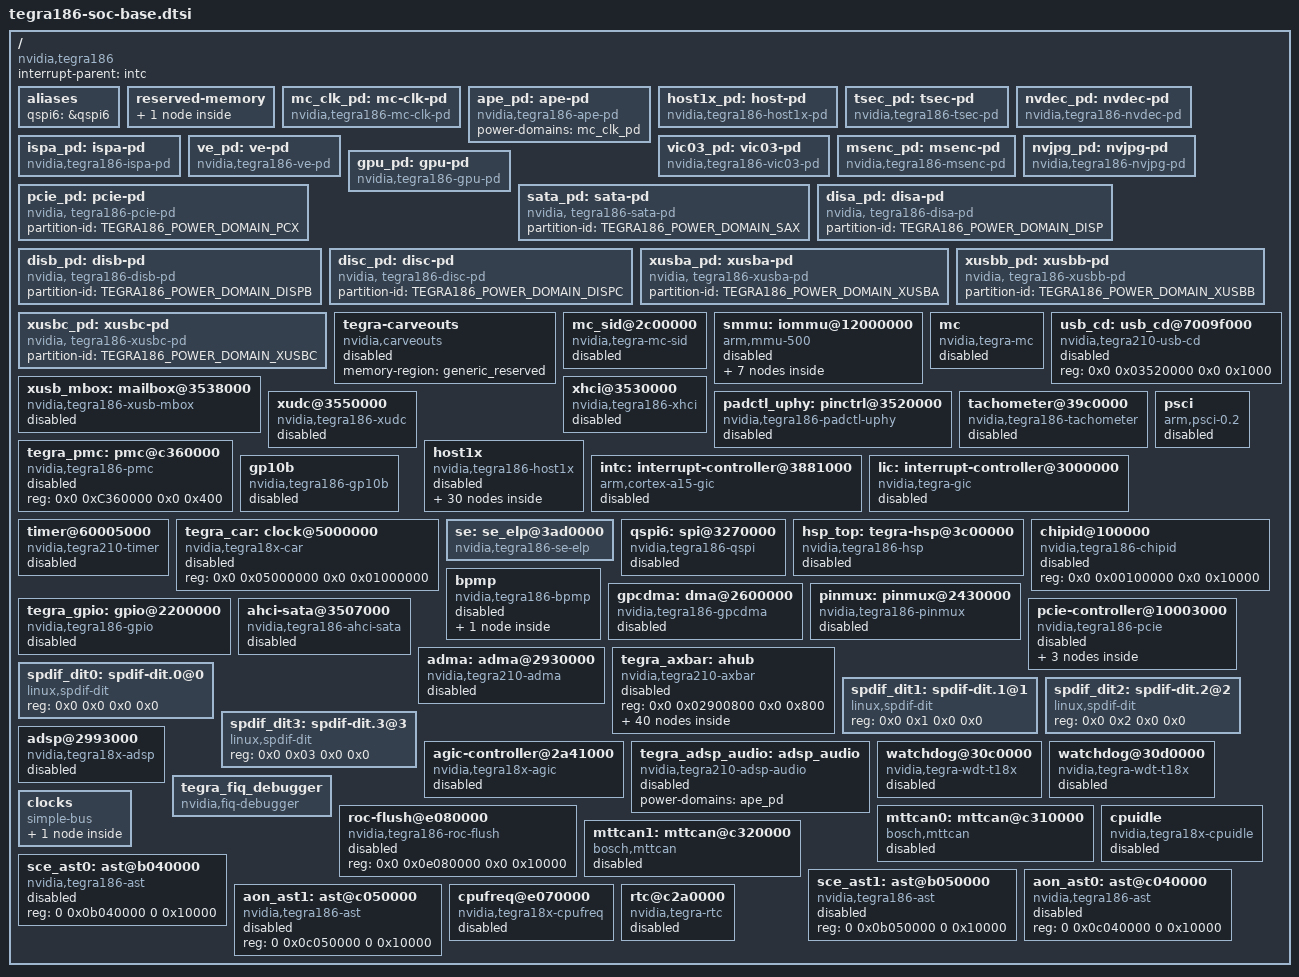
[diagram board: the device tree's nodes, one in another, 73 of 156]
/*
 * tegra186-soc-base.dtsi: SoC Base DTSI file.
 *
 * Copyright (c) 2014-2015, NVIDIA CORPORATION.  All rights reserved.
 *
 * This program is free software; you can redistribute it and/or modify
 * it under the terms of the GNU General Public License as published by
 * the Free Software Foundation; version 2 of the License.
 *
 * This program is distributed in the hope that it will be useful, but WITHOUT
 * ANY WARRANTY; without even the implied warranty of MERCHANTABILITY or
 * FITNESS FOR A PARTICULAR PURPOSE.  See the GNU General Public License for
 * more details.
 *
 * You should have received a copy of the GNU General Public License along
 * with this program; if not, write to the Free Software Foundation, Inc.,
 * 51 Franklin Street, Fifth Floor, Boston, MA  02110-1301, USA.
 *
 */

#include <dt-bindings/memory/tegra-swgroup.h>
#include <dt-bindings/memory/tegra186-swgroup.h>
#include <dt-bindings/display/tegra-dc.h>
#include "../../../../include/dt-bindings/clock/tegra186-clock.h"
#include "../../../../include/dt-bindings/reset/tegra186-reset.h"
#include "../../../../include/dt-bindings/interrupt/tegra186-irq.h"
#include "tegra186-soc/tegra186-sdhci.dtsi"
#include "tegra186-soc/tegra186-soc-ufshc.dtsi"
#include "tegra186-soc/tegra186-soc-i2c.dtsi"
#include "tegra186-soc/tegra186-soc-spi.dtsi"
#include "tegra186-soc/tegra186-soc-pwm.dtsi"
#include "../../../../include/dt-bindings/soc/tegra186-powergate.h"
#include "../../../../include/dt-bindings/pinctrl/pinctrl-tegra-padctl-uphy.h"
#include "tegra186-soc/tegra186-soc-uart.dtsi"
#include "tegra186-soc/tegra186-soc-eqos.dtsi"

/ {
	compatible = "nvidia,tegra186";
	interrupt-parent = <&intc>;
	#address-cells = <2>;
	#size-cells = <2>;

	aliases {
		qspi6 = &qspi6;
	};

	reserved-memory {
		#address-cells = <2>;
		#size-cells = <2>;
		ranges;

		generic_reserved: generic_carveout {
			compatible = "nvidia,generic_carveout";
			size = <0 0x20000000>;
			alignment = <0 0x100000>;
			no-map;
			status = "disabled";
		};
	};

	mc_clk_pd: mc-clk-pd {
		compatible = "nvidia,tegra186-mc-clk-pd";
		#power-domain-cells = <0>;
	};

	ape_pd: ape-pd {
		compatible = "nvidia,tegra186-ape-pd";
		#power-domain-cells = <0>;
		power-domains = <&mc_clk_pd>;
	};

	host1x_pd: host-pd {
		compatible = "nvidia,tegra186-host1x-pd";
		is_off;
		host1x;
		#power-domain-cells = <0>;
		power-domains = <&mc_clk_pd>;
	};

	tsec_pd: tsec-pd {
		compatible = "nvidia,tegra186-tsec-pd";
		is_off;
		#power-domain-cells = <0>;
		power-domains = <&host1x_pd>;
	};

	nvdec_pd: nvdec-pd {
		compatible = "nvidia,tegra186-nvdec-pd";
		is_off;
		#power-domain-cells = <0>;
		power-domains = <&host1x_pd>;
		partition-id = <TEGRA186_POWER_DOMAIN_NVDEC>;
	};

	ispa_pd: ispa-pd {
		compatible = "nvidia,tegra186-ispa-pd";
		is_off;
		#power-domain-cells = <0>;
		power-domains = <&host1x_pd>;
		partition-id = <TEGRA186_POWER_DOMAIN_ISPA>;
	};

	ve_pd: ve-pd {
		compatible = "nvidia,tegra186-ve-pd";
		is_off;
		#power-domain-cells = <0>;
		power-domains = <&host1x_pd>;
		partition-id = <TEGRA186_POWER_DOMAIN_VE>;
	};

	vic03_pd: vic03-pd {
		compatible = "nvidia,tegra186-vic03-pd";
		is_off;
		#power-domain-cells = <0>;
		power-domains = <&host1x_pd>;
		partition-id = <TEGRA186_POWER_DOMAIN_VIC>;
	};

	msenc_pd: msenc-pd {
		compatible = "nvidia,tegra186-msenc-pd";
		is_off;
		#power-domain-cells = <0>;
		power-domains = <&host1x_pd>;
		partition-id = <TEGRA186_POWER_DOMAIN_MPE>;
	};

	nvjpg_pd: nvjpg-pd {
		compatible = "nvidia,tegra186-nvjpg-pd";
		is_off;
		#power-domain-cells = <0>;
		power-domains = <&host1x_pd>;
		partition-id = <TEGRA186_POWER_DOMAIN_NVJPG>;
	};

	gpu_pd: gpu-pd {
		compatible = "nvidia,tegra186-gpu-pd";
		is_off;
		#power-domain-cells = <0>;
		power-domains = <&host1x_pd>;
		partition-id = <TEGRA186_POWER_DOMAIN_GPU>;
	};

	pcie_pd: pcie-pd {
		compatible = "nvidia, tegra186-pcie-pd";
		#power-domain-cells = <0>;
		partition-id = <TEGRA186_POWER_DOMAIN_PCX>;
	};

	sata_pd: sata-pd {
		compatible = "nvidia, tegra186-sata-pd";
		#power-domain-cells = <0>;
		partition-id = <TEGRA186_POWER_DOMAIN_SAX>;
	};

	disa_pd: disa-pd {
		compatible = "nvidia, tegra186-disa-pd";
		#power-domain-cells = <0>;
		partition-id = <TEGRA186_POWER_DOMAIN_DISP>;
	};

	disb_pd: disb-pd {
		compatible = "nvidia, tegra186-disb-pd";
		#power-domain-cells = <0>;
		partition-id = <TEGRA186_POWER_DOMAIN_DISPB>;
	};

	disc_pd: disc-pd {
		compatible = "nvidia, tegra186-disc-pd";
		#power-domain-cells = <0>;
		partition-id = <TEGRA186_POWER_DOMAIN_DISPC>;
	};

	xusba_pd: xusba-pd {
		compatible = "nvidia, tegra186-xusba-pd";
		#power-domain-cells = <0>;
		partition-id = <TEGRA186_POWER_DOMAIN_XUSBA>;
	};

	xusbb_pd: xusbb-pd {
		compatible = "nvidia, tegra186-xusbb-pd";
		#power-domain-cells = <0>;
		partition-id = <TEGRA186_POWER_DOMAIN_XUSBB>;
	};

	xusbc_pd: xusbc-pd {
		compatible = "nvidia, tegra186-xusbc-pd";
		#power-domain-cells = <0>;
		partition-id = <TEGRA186_POWER_DOMAIN_XUSBC>;
	};

	tegra-carveouts {
		compatible = "nvidia,carveouts";
		memory-region = <&generic_reserved>;
		status = "disabled";
	};

	mc_sid@2c00000 {
		compatible = "nvidia,tegra-mc-sid";
 		reg = <0x0 0x02c00000 0x0 0x00010000>, /* MC_SID_BASE */
 		      <0x0 0x02c10000 0x0 0x00010000>; /* MC_BASE */
		status = "disabled";
	};

	/* HACK: Populate earlier than other device */
	smmu: iommu@12000000{
		compatible = "arm,mmu-500";
		reg = <0x0 0x12000000 0x0 0x01000000>; /* 16MB */
		#global-interrupts = <2>;
		interrupts = <0 170 4>,
			     <0 171 4>;

		mmu-masters = <&{/gp10b}		TEGRA_SWGROUP_GPUB>,
			      <&host1x			TEGRA_SWGROUP_HC>,
			      <&{/host1x/nvcsi@150c0000}	TEGRA_SWGROUP_NVCSI>,
			      <&{/host1x/vic@15340000}		TEGRA_SWGROUP_VIC>,
			      <&{/host1x/vi@15700000}		TEGRA_SWGROUP_VI>,
			      <&{/host1x/isp@15600000}		TEGRA_SWGROUP_ISP>,
			      <&{/host1x/nvdec@15480000}	TEGRA_SWGROUP_NVDEC>,
			      <&{/host1x/nvenc@154c0000}	TEGRA_SWGROUP_NVENC>,
			      <&{/host1x/nvjpg@15380000}		TEGRA_SWGROUP_NVJPG>,
			      <&{/host1x/nvdisplay@15200000}	TEGRA_SWGROUP_NVDISPLAY>,
			      <&{/host1x/nvdisplay@15210000}	TEGRA_SWGROUP_NVDISPLAY>,
			      <&{/host1x/nvdisplay@15220000}	TEGRA_SWGROUP_NVDISPLAY>,
			      <&{/host1x/tsec@15500000}		TEGRA_SWGROUP_TSEC>,
			      <&{/host1x/tsecb@15100000}	TEGRA_SWGROUP_TSECB>,
			      <&{/host1x/se@15810000}		TEGRA_SWGROUP_SE>,
			      <&{/host1x/se@15820000}		TEGRA_SWGROUP_SE1>,
			      <&{/host1x/se@15830000}		TEGRA_SWGROUP_SE2>,
			      <&{/host1x/se@15840000}		TEGRA_SWGROUP_SE3>,
			      <&{/sdhci@3460000}	TEGRA_SWGROUP_SDMMC4A>,
			      <&{/sdhci@3440000}	TEGRA_SWGROUP_SDMMC3A>,
			      <&{/sdhci@3420000}	TEGRA_SWGROUP_SDMMC2A>,
			      <&{/sdhci@3400000}	TEGRA_SWGROUP_SDMMC1A>,
			      <&{/xhci@3530000}		TEGRA_SWGROUP_XUSB_HOST>,
			      <&{/xudc@3550000}		TEGRA_SWGROUP_XUSB_DEV>,
			      <&{/ahci-sata@3507000}	TEGRA_SWGROUP_SATA2>,
			      <&{/bpmp}			TEGRA_SWGROUP_BPMP>,
			      <&{/dma@2600000}		TEGRA_SWGROUP_AXIS>,
			      <&host1x_ctx0		TEGRA_SWGROUP_HOST1X_CTX0>,
			      <&host1x_ctx1		TEGRA_SWGROUP_HOST1X_CTX1>,
			      <&host1x_ctx2		TEGRA_SWGROUP_HOST1X_CTX2>,
			      <&host1x_ctx3		TEGRA_SWGROUP_HOST1X_CTX3>,
			      <&host1x_ctx4		TEGRA_SWGROUP_HOST1X_CTX4>,
			      <&host1x_ctx5		TEGRA_SWGROUP_HOST1X_CTX5>,
			      <&host1x_ctx6		TEGRA_SWGROUP_HOST1X_CTX6>,
			      <&host1x_ctx7		TEGRA_SWGROUP_HOST1X_CTX7>;

		domains = <&ppcs_as TEGRA_SWGROUP_CELLS3(PPCS, PPCS1, PPCS2)>,
			  <&gpu_as TEGRA_SWGROUP_CELLS(GPUB)>,
			  <&ape_as TEGRA_SWGROUP_CELLS(APE)>,
			  <&dc_as TEGRA_SWGROUP_CELLS3(DC, DC12, DCB)>,
			  <&host1x_as 0x008c0940 0x6002225a>, /* HC,ISP,NVENC,VI,VIC,TSEC,NVDEC,SE,NVJPG,SE1,TSECB,NVCSI,NVDISPLAY,SE2,SE3 */
			  <&host1x_as TEGRA_SWGROUP_CELLS(HOST1X_CTX0)>,
			  <&host1x_as TEGRA_SWGROUP_CELLS(HOST1X_CTX1)>,
			  <&host1x_as TEGRA_SWGROUP_CELLS(HOST1X_CTX2)>,
			  <&host1x_as TEGRA_SWGROUP_CELLS(HOST1X_CTX3)>,
			  <&host1x_as TEGRA_SWGROUP_CELLS(HOST1X_CTX4)>,
			  <&host1x_as TEGRA_SWGROUP_CELLS(HOST1X_CTX5)>,
			  <&host1x_as TEGRA_SWGROUP_CELLS(HOST1X_CTX6)>,
			  <&host1x_as TEGRA_SWGROUP_CELLS(HOST1X_CTX7)>,
			  <&common_as TEGRA_SWGROUP_CELLS(SDMMC1A)>,
			  <&common_as TEGRA_SWGROUP_CELLS(SDMMC2A)>,
			  <&common_as TEGRA_SWGROUP_CELLS(SDMMC3A)>,
			  <&common_as TEGRA_SWGROUP_CELLS(SDMMC4A)>,
			  <&common_as TEGRA_SWGROUP_CELLS(XUSB_HOST)>,
			  <&common_as TEGRA_SWGROUP_CELLS(XUSB_DEV)>,
			  <&common_as TEGRA_SWGROUP_CELLS(AXIS)>,
			  <&common_as TEGRA_SWGROUP_CELLS(BPMP)>,
			  <&common_as TEGRA_SWGROUP_CELLS(AFI)>;

		status = "disabled";

		address-space-prop {
			host1x_as: host1x {
				iova-start = <0x0 0x5a500000>;
				iova-size = <0x0 0x7FF00000>;
				alignment = <0xFFFFF>;
				num-pf-page = <0>;
				gap-page = <1>;
			};
			common_as: common {
				iova-start = <0x0 0x80000000>;
				iova-size = <0x0 0x7FF00000>;
				alignment = <0xFFFFF>;
				num-pf-page = <0>;
				gap-page = <1>;
			};
			ppcs_as: ppcs {
				iova-start = <0x0 0x80000000>;
				iova-size = <0x0 0x7FF00000>;
				alignment = <0xFFFFF>;
				num-pf-page = <1>;
				gap-page = <1>;
			};
			dc_as: dc {
				iova-start = <0x0 0x00010000>;
				iova-size = <0x0 0xFFFEFFFF>;
				alignment = <0xFFFFF>;
				num-pf-page = <0>;
				gap-page = <0>;
			};
			gpu_as: gpu {
				iova-start = <0x0 0x00100000>;
				iova-size = <0x0 0xFFEFFFFF>;
				alignment = <0xFFFFF>;
				num-pf-page = <0>;
				gap-page = <0>;
			};
			ape_as: ape {
				iova-start = <0x0 0x40000000>;
				iova-size = <0x0 0xC0000000>;
				alignment = <0xFFFFF>;
				num-pf-page = <0>;
				gap-page = <1>;
			};
		};
	};

	mc {
		compatible = "nvidia,tegra-mc";

		reg-ranges = <1>;
		reg        = <0x0 0x2c10000 0x0 0x1000   /* Broadcast channel */
			      0x0 0x2c20000 0x0 0x1000   /* MC0 */
			      0x0 0x2c30000 0x0 0x1000   /* MC1 */
			      0x0 0x2c40000 0x0 0x1000   /* MC2 */
			      0x0 0x2c50000 0x0 0x1000>; /* MC3 */

		interrupts = <0 223 0x4>;
		int_count  = <8>;
		int_mask   = <0xf3140>;

		channels   = <4>;
		status = "disabled";
        };

	usb_cd: usb_cd@7009f000 {
		compatible = "nvidia,tegra210-usb-cd";
		reg = <0x0 0x03520000 0x0 0x1000>;
		#extcon-cells = <1>;
		status = "disabled";
	};

	xusb_mbox: mailbox@3538000 {
		compatible = "nvidia,tegra186-xusb-mbox";
		reg = <0x0 0x03538000 0x0 0x1000>;
		interrupts = <0 164 0x4>;

		#mbox-cells = <0>;
		status = "disabled";
	};

	xhci@3530000 {
		compatible = "nvidia,tegra186-xhci";
		reg = <0x0 0x03530000 0x0 0x8000>,
			<0x0 0x03538000 0x0 0x1000>;
		interrupts = <0 163 0x4>;
		mboxes = <&xusb_mbox>;
		mbox-names = "xusb";
		#stream-id-cells = <1>;
		status = "disabled";
	};

	xudc@3550000 {
		compatible = "nvidia,tegra186-xudc";
		reg = <0x0 0x03550000 0x0 0x8000>,
			<0x0 0x03558000 0x0 0x1000>;
		interrupts = <0 166 0x4>;
		#stream-id-cells = <1>;
		status = "disabled";
	};

	padctl_uphy: pinctrl@3520000 {
		compatible = "nvidia,tegra186-padctl-uphy";
		reg = <0x0 0x03520000 0x0 0x1000>,
			<0x0 0x03540000 0x0 0x1000>,
			<0x0 0x02500000 0x0 0xa0000>;
		reg-names = "padctl", "ao", "uphy";
		resets = <&tegra_car TEGRA186_RESET_UPHY>,
			<&tegra_car TEGRA186_RESET_PEX_USB_UPHY>,
			<&tegra_car TEGRA186_RESET_PEX_USB_UPHY_PLL0>,
			<&tegra_car TEGRA186_RESET_PEX_USB_UPHY_PLL1>,
			<&tegra_car TEGRA186_RESET_PEX_USB_UPHY_L0>,
			<&tegra_car TEGRA186_RESET_PEX_USB_UPHY_L1>,
			<&tegra_car TEGRA186_RESET_PEX_USB_UPHY_L2>,
			<&tegra_car TEGRA186_RESET_PEX_USB_UPHY_L3>,
			<&tegra_car TEGRA186_RESET_PEX_USB_UPHY_L4>,
			<&tegra_car TEGRA186_RESET_PEX_USB_UPHY_L5>;
		reset-names = "uphy_rst", "uphy_master_rst", "uphy_pll0_rst", "uphy_pll1_rst", "uphy_lane0_rst",
			"uphy_lane1_rst", "uphy_lane2_rst", "uphy_lane3_rst", "uphy_lane4_rst", "uphy_lane5_rst";
		clocks = <&tegra_car TEGRA186_CLK_USB2_TRK>,
			<&tegra_car TEGRA186_CLK_HSIC_TRK>;
		clock-names = "usb2_trk", "hsic_trk";
		interrupts = <0 167 0x4>;
		mboxes = <&xusb_mbox>;
		mbox-names = "xusb";
		#phy-cells = <1>;
		status = "disabled";
	};

	tachometer@39c0000 {
		compatible = "nvidia,tegra186-tachometer";
		reg = <0x0 0x039c0000 0x0 0x10>;
		#stream-id-cells = <1>;
		clocks = <&tegra_car TEGRA186_CLK_TACH>;
		clock-names = "tach";
		resets = <&tegra_car TEGRA186_RESET_TACH>;
		reset-names = "tach";
		pulse-per-rev = <1>;
		sampling-window = <1>;
		status = "disabled";
	};

	tegra_pmc: pmc@c360000 {
		compatible = "nvidia,tegra186-pmc";
		reg = <0x0 0xC360000 0x0 0x400>;
		#padcontroller-cells = <1>;
		status = "disabled";
	};

	host1x: host1x {
		compatible = "nvidia,tegra186-host1x", "simple-bus";
		reg = <0x0 0x13e10000 0x0 0x00010000
			0x0 0x13e00000 0x0 0x00010000
			0x0 0x13ec0000 0x0 0x00040000>;
		interrupts = <0 265 0x04
				0 263 0x04>;

		power-domains = <&host1x_pd>;
		wakeup_capable;
		resets = <&tegra_car TEGRA186_RESET_HOST1X>;
		clocks = <&tegra_car TEGRA186_CLK_HOST1X>,
			 <&tegra_car TEGRA186_CLK_ACTMON>;
		clock-names = "host1x", "actmon";
		nvidia,vmid = <1>;

		#stream-id-cells = <1>;

		#address-cells = <2>;
		#size-cells = <2>;

		ranges;
		status = "disabled";

		host1x_ctx0: ctx0 {
			compatible = "nvidia,tegra186-iommu-context";
			#stream-id-cells = <1>;
			status = "disabled";
		};

		host1x_ctx1: ctx1 {
			compatible = "nvidia,tegra186-iommu-context";
			#stream-id-cells = <1>;
			status = "disabled";
		};

		host1x_ctx2: ctx2 {
			compatible = "nvidia,tegra186-iommu-context";
			#stream-id-cells = <1>;
			status = "disabled";
		};

		host1x_ctx3: ctx3 {
			compatible = "nvidia,tegra186-iommu-context";
			#stream-id-cells = <1>;
			status = "disabled";
		};

		host1x_ctx4: ctx4 {
			compatible = "nvidia,tegra186-iommu-context";
			#stream-id-cells = <1>;
			status = "disabled";
		};

		host1x_ctx5: ctx5 {
			compatible = "nvidia,tegra186-iommu-context";
			#stream-id-cells = <1>;
			status = "disabled";
		};

		host1x_ctx6: ctx6 {
			compatible = "nvidia,tegra186-iommu-context";
			#stream-id-cells = <1>;
			status = "disabled";
		};

		host1x_ctx7: ctx7 {
			compatible = "nvidia,tegra186-iommu-context";
			#stream-id-cells = <1>;
			status = "disabled";
		};

		nvcsi@150c0000 {
			compatible = "nvidia,tegra186-nvcsi";
			power-domains = <&ve_pd>;
			reg = <0x0 0x150c0000 0x0 0x00040000>;
			resets = <&tegra_car TEGRA186_RESET_NVCSI>;
			clocks = <&tegra_car TEGRA186_CLK_NVCSI>,
				 <&tegra_car TEGRA186_CLK_NVCSILP>;
			clock-names = "nvcsi", "nvcsilp";
			interrupts = <0 119 0x04>;
			#stream-id-cells = <1>;
			status = "disabled";
		};

		vi@15700000 {
			compatible = "nvidia,tegra186-vi";
			power-domains = <&ve_pd>;
                        reg = <0x0 0x15700000 0x0 0x00100000>;
                        interrupts = <0 201 0x04
                                      0 202 0x04
                                      0 203 0x04>;
			resets = <&tegra_car TEGRA186_RESET_VI>;
			clocks = <&tegra_car TEGRA186_CLK_VI>,
				 <&tegra_car TEGRA186_CLK_EMC>;
			clock-names = "vi", "emc";
			#stream-id-cells = <1>;
			status = "disabled";
		};

		isp@15600000 {
			compatible = "nvidia,tegra186-isp";
			power-domains = <&ispa_pd>;
                        reg = <0x0 0x15600000 0x0 0x00040000>;
                        interrupts = <0 205 0x04>;
			resets = <&tegra_car TEGRA186_RESET_ISP>;
			clocks = <&tegra_car TEGRA186_CLK_ISP>;
			clock-names = "isp";
			#stream-id-cells = <1>;
			status = "disabled";
		};

		vii2c@156c0000 {
			compatible = "nvidia,tegra186-vii2c";
			reg = <0x0 0x156c0000 0x0 0x00040000>;
			status = "disabled";
		};

		nvdisplay@15200000 {
			compatible = "nvidia,tegra186-dc";
			power-domains = <&mc_clk_pd>;
			reg = <0x0 0x15200000 0x0 0x10000>;
			interrupts = <0 153 0x04>;
			win-mask = <0x7>;
			#stream-id-cells = <1>;
			clocks = <&clk32k_in>,
				 <&tegra_car TEGRA186_CLK_NVDISPLAY_DISP>,
				 <&tegra_car TEGRA186_CLK_NVDISPLAYHUB>,
				 <&tegra_car TEGRA186_CLK_NVDISPLAY_P0>,
				 <&tegra_car TEGRA186_CLK_PLLD2>,
				 <&tegra_car TEGRA186_CLK_EMC>,
				 <&tegra_car TEGRA186_CLK_EMC_LATENCY>;
			clock-names = "clk32k_in", "nvdisplay_disp",
				      "nvdisplayhub", "nvdisplay_p0", "plld2",
				      "emc", "emc_latency";
			resets = <&tegra_car TEGRA186_RESET_NVDISPLAY0_MISC>,
				 <&tegra_car TEGRA186_RESET_NVDISPLAY0_WGRP0>,
				 <&tegra_car TEGRA186_RESET_NVDISPLAY0_WGRP1>,
				 <&tegra_car TEGRA186_RESET_NVDISPLAY0_WGRP2>,
				 <&tegra_car TEGRA186_RESET_NVDISPLAY0_WGRP3>,
				 <&tegra_car TEGRA186_RESET_NVDISPLAY0_WGRP4>,
				 <&tegra_car TEGRA186_RESET_NVDISPLAY0_WGRP5>,
				 <&tegra_car TEGRA186_RESET_NVDISPLAY0_HEAD0>;
			reset-names = "misc", "wgrp0", "wgrp1", "wgrp2",
				      "wrgp3", "wgrp4", "wgrp5", "head0";
			status = "disabled";
		};

		nvdisplay@15210000 {
			compatible = "nvidia,tegra186-dc";
			power-domains = <&mc_clk_pd>;
                        reg = <0x0 0x15210000 0x0 0x10000>;
                        interrupts = <0 154 0x04>;
			win-mask = <0x38>;
			#stream-id-cells = <1>;
			clocks = <&clk32k_in>,
				 <&tegra_car TEGRA186_CLK_NVDISPLAY_DISP>,
				 <&tegra_car TEGRA186_CLK_NVDISPLAYHUB>,
				 <&tegra_car TEGRA186_CLK_NVDISPLAY_P1>,
				 <&tegra_car TEGRA186_CLK_PLLD2>,
				 <&tegra_car TEGRA186_CLK_EMC>,
				 <&tegra_car TEGRA186_CLK_EMC_LATENCY>;
			clock-names = "clk32k_in", "nvdisplay_disp",
				      "nvdisplayhub", "nvdisplay_p1", "plld2",
				      "emc", "emc_latency";
			resets = <&tegra_car TEGRA186_RESET_NVDISPLAY0_MISC>,
				 <&tegra_car TEGRA186_RESET_NVDISPLAY0_WGRP0>,
				 <&tegra_car TEGRA186_RESET_NVDISPLAY0_WGRP1>,
				 <&tegra_car TEGRA186_RESET_NVDISPLAY0_WGRP2>,
				 <&tegra_car TEGRA186_RESET_NVDISPLAY0_WGRP3>,
				 <&tegra_car TEGRA186_RESET_NVDISPLAY0_WGRP4>,
				 <&tegra_car TEGRA186_RESET_NVDISPLAY0_WGRP5>,
				 <&tegra_car TEGRA186_RESET_NVDISPLAY0_HEAD1>;
			reset-names = "misc", "wgrp0", "wgrp1", "wgrp2",
				      "wrgp3", "wgrp4", "wgrp5", "head1";
			status = "disabled";
		};

		nvdisplay@15220000 {
			compatible = "nvidia,tegra186-dc";
			power-domains = <&mc_clk_pd>;
                        reg = <0x0 0x15220000 0x0 0x10000>;
                        interrupts = <0 155 0x04>;
			win-mask = <0x0>;
			#stream-id-cells = <1>;
			clocks = <&clk32k_in>,
				 <&tegra_car TEGRA186_CLK_NVDISPLAY_DISP>,
				 <&tegra_car TEGRA186_CLK_NVDISPLAYHUB>,
				 <&tegra_car TEGRA186_CLK_NVDISPLAY_P2>,
				 <&tegra_car TEGRA186_CLK_PLLD2>,
				 <&tegra_car TEGRA186_CLK_EMC>,
				 <&tegra_car TEGRA186_CLK_EMC_LATENCY>;
			clock-names = "clk32k_in", "nvdisplay_disp",
				      "nvdisplayhub", "nvdisplay_p2", "plld2",
				      "emc", "emc_latency";
			resets = <&tegra_car TEGRA186_RESET_NVDISPLAY0_MISC>,
				 <&tegra_car TEGRA186_RESET_NVDISPLAY0_WGRP0>,
				 <&tegra_car TEGRA186_RESET_NVDISPLAY0_WGRP1>,
				 <&tegra_car TEGRA186_RESET_NVDISPLAY0_WGRP2>,
				 <&tegra_car TEGRA186_RESET_NVDISPLAY0_WGRP3>,
				 <&tegra_car TEGRA186_RESET_NVDISPLAY0_WGRP4>,
				 <&tegra_car TEGRA186_RESET_NVDISPLAY0_WGRP5>,
				 <&tegra_car TEGRA186_RESET_NVDISPLAY0_HEAD2>;
			reset-names = "misc", "wgrp0", "wgrp1", "wgrp2",
				      "wrgp3", "wgrp4", "wgrp5", "head2";
			status = "disabled";
		};

		dsi {	/* dsi@15300000 */
			compatible = "nvidia,tegra186-dsi";
			reg = <0x0 0x15300000 0x0 0x00040000>, /* DSIA */
			      <0x0 0x15400000 0x0 0x00040000>, /* DSIB */
			      <0x0 0x15900000 0x0 0x00040000>, /* DSIC */
			      <0x0 0x15940000 0x0 0x00040000>, /* DSID */
			      <0x0 0x15880000 0x0 0x00010000>; /* PADCTL REG */
			clocks = <&clk32k_in>,
				 <&tegra_car TEGRA186_CLK_DSI>,
				 <&tegra_car TEGRA186_CLK_DSIA_LP>,
				 <&tegra_car TEGRA186_CLK_DSIB>,
				 <&tegra_car TEGRA186_CLK_DSIB_LP>,
				 <&tegra_car TEGRA186_CLK_DSIC>,
				 <&tegra_car TEGRA186_CLK_DSIC_LP>,
				 <&tegra_car TEGRA186_CLK_DSID>,
				 <&tegra_car TEGRA186_CLK_DSID_LP>;
			clock-names = "clk32k_in", "dsi", "dsia_lp",
					"dsib", "dsib_lp", "dsic", "dsic_lp",
					"dsid", "dsid_lp";
			resets = <&tegra_car TEGRA186_RESET_DSI>,
				<&tegra_car TEGRA186_RESET_DSIB>,
				<&tegra_car TEGRA186_RESET_DSIC>,
				<&tegra_car TEGRA186_RESET_DSID>,
				<&tegra_car TEGRA186_RESET_DSIPADCTL>;
			reset-names = "dsi";
			status = "disabled";
		};

		vic@15340000 {
			compatible = "nvidia,tegra186-vic";
			power-domains = <&vic03_pd>;
			reg = <0x0 0x15340000 0x0 0x00040000>;
			resets = <&tegra_car TEGRA186_RESET_VIC>;
			clocks = <&tegra_car TEGRA186_CLK_VIC>,
				 <&tegra_car TEGRA186_CLK_EMC>,
				 <&clk32k_in>,
				 <&clk32k_in>;
			clock-names = "vic", "emc", "vic_floor", "emc_shared";
			#stream-id-cells = <1>;
			status = "disabled";
		};

		nvenc@154c0000 {
			compatible = "nvidia,tegra186-nvenc";
			power-domains = <&msenc_pd>;
			reg = <0x0 0x154c0000 0x0 0x00040000>;
			resets = <&tegra_car TEGRA186_RESET_NVENC>;
			clocks = <&tegra_car TEGRA186_CLK_NVENC>,
				 <&tegra_car TEGRA186_CLK_EMC>;
			clock-names = "nvenc", "emc";
			#stream-id-cells = <1>;
			status = "disabled";
		};

		nvdec@15480000 {
			compatible = "nvidia,tegra186-nvdec";
			power-domains = <&nvdec_pd>;
			reg = <0x0 0x15480000 0x0 0x00040000>;
			resets = <&tegra_car TEGRA186_RESET_NVDEC>;
			clocks = <&tegra_car TEGRA186_CLK_NVDEC>,
				 <&tegra_car TEGRA186_CLK_KFUSE>,
				 <&tegra_car TEGRA186_CLK_EMC>;
			clock-names = "nvdec", "kfuse", "emc";
			#stream-id-cells = <1>;
			status = "disabled";
		};

		nvjpg@15380000 {
			compatible = "nvidia,tegra186-nvjpg";
			power-domains = <&nvjpg_pd>;
			reg = <0x0 0x15380000 0x0 0x00040000>;
			resets = <&tegra_car TEGRA186_RESET_NVJPG>;
			clocks = <&tegra_car TEGRA186_CLK_NVJPG>,
				 <&tegra_car TEGRA186_CLK_EMC>;
			clock-names = "nvjpg", "emc";
			#stream-id-cells = <1>;
			status = "disabled";
		};

		tsec@15500000 {
			compatible = "nvidia,tegra186-tsec";
			power-domains = <&tsec_pd>;
			reg = <0x0 0x15500000 0x0 0x00040000>;
			resets = <&tegra_car TEGRA186_RESET_TSEC>;
			clocks = <&tegra_car TEGRA186_CLK_TSEC>,
				 <&tegra_car TEGRA186_CLK_EMC>;
			clock-names = "tsec", "emc";
			#stream-id-cells = <1>;
			status = "disabled";
		};

		tsecb@15100000 {
			compatible = "nvidia,tegra186-tsec";
			power-domains = <&tsec_pd>;
			reg = <0x0 0x15100000 0x0 0x00040000>;
			resets = <&tegra_car TEGRA186_RESET_TSECB>;
			clocks = <&tegra_car TEGRA186_CLK_TSECB>,
				 <&tegra_car TEGRA186_CLK_EMC>;
			clock-names = "tsecb", "emc";
			#stream-id-cells = <1>;
			status = "disabled";
		};

		sor@15540000 {
			compatible = "nvidia,tegra186-sor";
			reg = <0x0 0x15540000 0x0 0x00040000>;
			nvidia,xbar-ctrl = <2 1 0 3 4>;
			clocks = <&clk32k_in>,
				 <&tegra_car TEGRA186_CLK_SOR0>,
				 <&tegra_car TEGRA186_CLK_SOR_SAFE>;
			clock-names = "clk32k_in", "sor0", "sor_safe";
			resets = <&tegra_car TEGRA186_RESET_SOR0>;
			reset-names = "sor0";
			status = "disabled";
		};

		sor1@15580000 {
			compatible = "nvidia,tegra186-sor1";
			reg = <0x0 0x15580000 0x0 0x00040000>;
			interrupts = <0 158 0x4>; /* INT_SOR_1 */
			nvidia,xbar-ctrl = <2 1 0 3 4>;
			clocks = <&clk32k_in>,
				 <&tegra_car TEGRA186_CLK_SOR1>,
				 <&tegra_car TEGRA186_CLK_SOR_SAFE>;
			clock-names = "clk32k_in", "sor1", "sor_safe";
			resets = <&tegra_car TEGRA186_RESET_SOR1>;
			reset-names = "sor1";
			status = "disabled";
		};

		dpaux@155c0000 {
			compatible = "nvidia,tegra186-dpaux";
			reg = <0x0 0x155c0000 0x0 0x00040000>;
			interrupts = <0 159 0x4>; /* INT_DPAUX */
			clocks = <&clk32k_in>,
				 <&tegra_car TEGRA186_CLK_DPAUX>,
				 <&tegra_car TEGRA186_CLK_PLLDP>;
			clock-names = "clk32k_in", "dpaux", "plldp";
			resets = <&tegra_car TEGRA186_RESET_DPAUX>;
			reset-names = "dpaux";
			status = "disabled";
		};

		dpaux@15040000 {
			compatible = "nvidia,tegra186-dpaux1";
			reg = <0x0 0x15040000 0x0 0x00040000>;
			interrupts = <0 160 0x4>; /* INT_DPAUX_1 */
			clocks = <&clk32k_in>,
				 <&tegra_car TEGRA186_CLK_DPAUX1>,
				 <&tegra_car TEGRA186_CLK_PLLDP>;
			clock-names = "clk32k_in", "dpaux1", "plldp";
			resets = <&tegra_car TEGRA186_RESET_DPAUX1>;
			reset-names = "dpaux1";
			status = "disabled";
		};

		se@15810000 {
			compatible = "nvidia,tegra186-se-nvhost";
			power-domains = <&mc_clk_pd>;
			reg = <0x0 0x15810000 0x0 0x10000>;
			resets = <&tegra_car TEGRA186_RESET_SE>;
			clocks = <&tegra_car TEGRA186_CLK_SE>,
				 <&tegra_car TEGRA186_CLK_EMC>,
				 <&tegra_car TEGRA186_CLK_ENTROPY>;
			clock-names = "se", "emc", "entropy";
			#stream-id-cells = <1>;
			status = "disabled";
		};

		se@15820000 {
			compatible = "nvidia,tegra186-se-nvhost";
			power-domains = <&mc_clk_pd>;
			reg = <0x0 0x15820000 0x0 0x10000>;
			resets = <&tegra_car TEGRA186_RESET_SE>;
			clocks = <&tegra_car TEGRA186_CLK_SE>,
				 <&tegra_car TEGRA186_CLK_EMC>,
				 <&tegra_car TEGRA186_CLK_ENTROPY>;
			clock-names = "se", "emc", "entropy";
			#stream-id-cells = <1>;
			status = "disabled";
		};

		se@15830000 {
			compatible = "nvidia,tegra186-se-nvhost";
			power-domains = <&mc_clk_pd>;
			reg = <0x0 0x15830000 0x0 0x10000>;
			resets = <&tegra_car TEGRA186_RESET_SE>;
			clocks = <&tegra_car TEGRA186_CLK_SE>,
				 <&tegra_car TEGRA186_CLK_EMC>,
				 <&tegra_car TEGRA186_CLK_ENTROPY>;
			clock-names = "se", "emc", "entropy";
			#stream-id-cells = <1>;
			status = "disabled";
		};

		se@15840000 {
			compatible = "nvidia,tegra186-se-nvhost";
			power-domains = <&mc_clk_pd>;
			reg = <0x0 0x15840000 0x0 0x10000>;
			resets = <&tegra_car TEGRA186_RESET_SE>;
			clocks = <&tegra_car TEGRA186_CLK_SE>,
				 <&tegra_car TEGRA186_CLK_EMC>,
				 <&tegra_car TEGRA186_CLK_ENTROPY>;
			clock-names = "se", "emc", "entropy";
			#stream-id-cells = <1>;
			status = "disabled";
		};
	};

	gp10b {
		compatible = "nvidia,tegra186-gp10b", "nvidia,gp10b";
		power-domains = <&gpu_pd>;
		reg = <0x0 0x17000000 0x0 0x1000000
		       0x0 0x18000000 0x0 0x1000000
		       0x0 0x03b41000 0x0 0x00001000>;
		interrupts = <0 70 0x04
			      0 71 0x04>;
		interrupt-names = "stall", "nonstall";
		nvidia,host1x = <&host1x>;
		#stream-id-cells = <1>;
		access-vpr-phys;
		status = "disabled";
	};

	psci {
		compatible = "arm,psci-0.2";
		method = "smc";
		cpu_off = <0x84000002>;
		cpu_on = <0xC4000003>;
		cpu_suspend = <0xC4000001>;
		status = "disabled";
	};

	intc: interrupt-controller@3881000 {
		compatible = "arm,cortex-a15-gic";
		#interrupt-cells = <3>;
		interrupt-controller;
		reg = <0x0 0x03881000 0x0 0x00001000
		       0x0 0x03882000 0x0 0x00002000>;
		status = "disabled";
	};

	lic: interrupt-controller@3000000 {
		compatible = "nvidia,tegra-gic";
		interrupt-controller;
		reg = <0x0 0x03000000 0x0 0x00000800
			0x0 0x03000800 0x0 0x00000800
			0x0 0x03001000 0x0 0x00000800
			0x0 0x03001800 0x0 0x00000800
			0x0 0x03002000 0x0 0x00000800
			0x0 0x03002800 0x0 0x00000800
			0x0 0x03003000 0x0 0x00000800
			0x0 0x03003800 0x0 0x00000800
			0x0 0x0300f800 0x0 0x00000800>;
		status = "disabled";
	};

	timer@60005000 {
		compatible = "nvidia,tegra210-timer";
		reg = <0x0 0x60005000 0x0 0x400>;
		interrupts = <0 176 4>,
			     <0 177 4>,
			     <0 178 4>,
			     <0 179 4>;
		clock-frequency = <38400000>;
		status = "disabled";
	};

	tegra_car: clock@5000000 {
		compatible = "nvidia,tegra18x-car";
		reg = <0x0 0x05000000 0x0 0x01000000>;
		#clock-cells = <1>;
		#reset-cells = <1>;
		status = "disabled";
	};

	se: se_elp@3ad0000 {
		compatible = "nvidia,tegra186-se-elp";
		reg = <0x0 0x03ad0000 0x0 0x10000>,
		      <0x0 0x03ae0000 0x0 0x10000>;
	};

	qspi6: spi@3270000 {
		compatible = "nvidia,tegra186-qspi";
		reg = <0x0 0x3270000 0x0 0x10000>;
		interrupts = < 0 35 0x04 >;
		#address-cells = <1>;
		#size-cells = <0>;
                nvidia,dma-request-selector = <&gpcdma 5>;
		iommus = <&smmu TEGRA_SWGROUP_AXIS>;
		dmas = <&gpcdma 5>, <&gpcdma 5>;
		dma-names = "rx", "tx";
		clocks = <&tegra_car TEGRA186_CLK_QSPI>;
		clock-names = "qspi";
		resets = <&tegra_car TEGRA186_RESET_QSPI>;
		reset-names = "qspi";
		status = "disabled";
	};

	hsp_top: tegra-hsp@3c00000 {
		compatible = "nvidia,tegra186-hsp";
		reg = <0x0 0x03c00000 0x0 0x000a0000>;
		interrupts = <0 176 0x4>;
		nvidia,num-SM = <0x8>;
		nvidia,num-AS = <0x2>;
		nvidia,num-SS = <0x2>;
		nvidia,num-DB = <0x7>;
		nvidia,num-SI = <0x8>;
		status = "disabled";
	};

	chipid@100000 {
		compatible = "nvidia,tegra186-chipid";
		reg = <0x0 0x00100000 0x0 0x10000>;
		status = "disabled";
	};

	bpmp {
		compatible = "nvidia,tegra186-bpmp";
		#stream-id-cells = <1>;
		reg = <0x0 0x0d000000 0x0 0x00800000>,
		      <0x0 0x3004e000 0x0 0x00001000>,
		      <0x0 0x3004f000 0x0 0x00001000>;
		status = "disabled";

		bpmpthermal: bpmpthermal {
			compatible = "nvidia,tegra186-bpmp-thermal";
			#thermal-sensor-cells = <1>;
			status = "disabled";
		};
	};

	gpcdma: dma@2600000 {
		compatible = "nvidia,tegra186-gpcdma";
		reg = <0x0 0x2600000 0x0 0x210000>;
		resets = <&tegra_car TEGRA186_RESET_GPCDMA>;
		reset-names = "gpcdma";
		interrupts = <0 75 0x04
			      0 76 0x04
			      0 77 0x04
			      0 78 0x04
			      0 79 0x04
			      0 80 0x04
			      0 81 0x04
			      0 82 0x04
			      0 83 0x04
			      0 84 0x04
			      0 85 0x04
			      0 86 0x04
			      0 87 0x04
			      0 88 0x04
			      0 89 0x04
			      0 90 0x04
			      0 91 0x04
			      0 92 0x04
			      0 93 0x04
			      0 94 0x04
			      0 95 0x04
			      0 96 0x04
			      0 97 0x04
			      0 98 0x04
			      0 99 0x04
			      0 100 0x04
			      0 101 0x04
			      0 102 0x04
			      0 103 0x04
			      0 104 0x04
			      0 105 0x04
			      0 106 0x04
			      0 107 0x04>;
		#dma-cells = <1>;
		#stream-id-cells = <1>;
		status = "disabled";
	};

	pinmux: pinmux@2430000 {
                compatible = "nvidia,tegra186-pinmux";
                reg = <0x0 0x2430000 0x0 0x15000
			0x0 0xc300000 0x0 0x4000>;
		#gpio-range-cells = <3>;
                status = "disabled";
        };

        tegra_gpio: gpio@2200000 {
                compatible = "nvidia,tegra186-gpio";
                reg = <0x0 0x2200000 0x0 0x15700
                        0x0 0xc2f0000 0x0 0x2000>;
                interrupts = <0 47 0x04
                        0 50 0x04
                        0 53 0x04
                        0 56 0x04
                        0 59 0x04
                        0 180 0x04
                        0 60 0x04>; /*AON GPIO */
                status = "disabled";
                gpio-ranges = <&pinmux 0 0 246>;
                #gpio-cells = <2>;
                gpio-controller;
		clocks = <&tegra_car TEGRA186_CLK_GPIO_CTL0>,
			 <&tegra_car TEGRA186_CLK_GPIO_CTL1>,
			 <&tegra_car TEGRA186_CLK_GPIO_CTL2>,
			 <&tegra_car TEGRA186_CLK_GPIO_CTL3>,
			 <&tegra_car TEGRA186_CLK_GPIO_CTL4>,
			 <&tegra_car TEGRA186_CLK_GPIO_CTL5>;
		clock-names = "gpio0-clk", "gpio1-clk",
			      "gpio2-clk", "gpio3-clk",
			      "gpio4-clk", "gpio5-clk";
		resets = <&tegra_car TEGRA186_RESET_GPIO_CTL0>,
			<&tegra_car TEGRA186_RESET_GPIO_CTL1>,
			<&tegra_car TEGRA186_RESET_GPIO_CTL2>,
			<&tegra_car TEGRA186_RESET_GPIO_CTL3>,
			<&tegra_car TEGRA186_RESET_GPIO_CTL4>,
			<&tegra_car TEGRA186_RESET_GPIO_CTL0>;
		reset-names = "gpio0", "gpio1",
				"gpio2", "gpio3",
				"gpio4", "gpio5";

                nvidia,gpio_mapping = < 0 0x12000
                                        0 0x13000
                                        0 0x13200
                                        0 0X13400
                                        0 0x12200
                                        0 0x12400
                                        0 0x14200
                                        0 0x11000
                                        0 0x10800
                                        0 0x15000
                                        0 0x15200
                                        0 0x11200
                                        0 0x15600
                                        0 0x10000
                                        0 0x10200
                                        0 0x14000
                                        0 0x10400
                                        0 0x10A00
                                        1 0x1200
                                        0 0x10600
                                        1 0x1400
                                        1 0x1800
                                        1 0x1A00
                                        0 0x11400
                                        0 0x11600
                                        1 0x1E00
                                        1 0x1A00
                                        0 0x12600
                                        0 0x15400
                                        (-1) (-1)
                                        1 0x1600
                                        1 0x1000>;
        };

	ahci-sata@3507000 {
		compatible = "nvidia,tegra186-ahci-sata";
		reg = <0x0 0x03507000 0x0 0x00002000>, /* SATA AHCI */
			<0x0 0x03501000 0x0 0x00006000>, /* SATA Config */
			<0x0 0x03500000 0x0 0x00001000>, /* SATA IPFS */
			<0x0 0x03A90000 0x0 0x00010000>; /* SATA AUX */
		interrupts = <0 197 0x04>;
		#stream-id-cells = <1>;
		clocks = <&tegra_car TEGRA186_CLK_SATA>,
			<&tegra_car TEGRA186_CLK_SATA_OOB>,
			<&tegra_car TEGRA186_CLK_PLLP>,
			<&tegra_car TEGRA186_CLK_PLLP_UPHY>;
		clock-names = "sata", "sata_oob", "pllp", "pllp_uphy";
		resets = <&tegra_car TEGRA186_RESET_SATA>,
			<&tegra_car TEGRA186_RESET_SATACOLD>;
		reset-names = "sata", "satacold";
		phys = <&padctl_uphy TEGRA_PADCTL_UPHY_SATA_P(0)>;
		phy-names = "sata-phy";
		status = "disabled";
	};

	pcie-controller@10003000 {
		compatible = "nvidia,tegra186-pcie";
		power-domains = <&mc_clk_pd>;
		device_type = "pci";
		reg = <0x0 0x10003000 0x0 0x00000800   /* PADS registers */
		       0x0 0x10003800 0x0 0x00000800   /* AFI registers */
		       0x0 0x40000000 0x0 0x10000000>; /* configuration space */
		reg-names = "pads", "afi", "cs";

		clocks = <&tegra_car TEGRA186_CLK_AFI>,
			<&tegra_car TEGRA186_CLK_PCIE>;
		clock-names = "afi", "pcie";

		resets = <&tegra_car TEGRA186_RESET_AFI>,
			<&tegra_car TEGRA186_RESET_PCIE>,
			<&tegra_car TEGRA186_RESET_PCIEXCLK>;
		reset-names = "afi", "pcie", "pciex";

		interrupts = <0 72 0x04>, /* controller interrupt */
			     <0 73 0x04>; /* MSI interrupt */
		interrupt-names = "intr", "msi";

		#interrupt-cells = <1>;
		interrupt-map-mask = <0 0 0 0>;
		interrupt-map = <0 0 0 0 &intc 0 72 0x04>;// check this

		bus-range = <0x00 0xff>;
		#address-cells = <3>;
		#size-cells = <2>;

		ranges = <0x82000000 0 0x10000000 0x0 0x10000000 0 0x00001000   /* port 0 configuration space */
			  0x82000000 0 0x10001000 0x0 0x10001000 0 0x00001000   /* port 1 configuration space */
			  0x82000000 0 0x10004000 0x0 0x10004000 0 0x00001000   /* port 2 configuration space */
			  0x81000000 0 0x0        0x0 0x50000000 0 0x00010000   /* downstream I/O (64 KiB) */
			  0x82000000 0 0x50100000 0x0 0x50100000 0 0x07F00000   /* non-prefetchable memory (127 MiB) */
			  0xc2000000 0 0x58000000 0x0 0x58000000 0 0x28000000>; /* prefetchable memory (640 MiB) */

		nvidia,lane-map = <0x04>;
		status = "disabled";

		pci@1,0 {
			device_type = "pci";
			assigned-addresses = <0x82000800 0 0x10000000 0 0x1000>;
			reg = <0x000800 0 0 0 0>;
			status = "disabled";

			#address-cells = <3>;
			#size-cells = <2>;
			ranges;

			nvidia,num-lanes = <4>;
		};

		pci@2,0 {
			device_type = "pci";
			assigned-addresses = <0x82001000 0 0x10001000 0 0x1000>;
			reg = <0x001000 0 0 0 0>;
			status = "disabled";

			#address-cells = <3>;
			#size-cells = <2>;
			ranges;

			nvidia,num-lanes = <1>;
		};

		pci@3,0 {
			device_type = "pci";
			assigned-addresses = <0x82001800 0 0x10004000 0 0x1000>;
			reg = <0x001800 0 0 0 0>;
			status = "disabled";

			#address-cells = <3>;
			#size-cells = <2>;
			ranges;

			nvidia,num-lanes = <1>;
		};

	};

	adma: adma@2930000 {
		compatible = "nvidia,tegra210-adma";
		reg = <0x0 0x02930000 0x0 0x10000>,	/* GLOBAL Reg */
		      <0x0 0x02940000 0x0 0x10000>,	/* PAGE1 */
		      <0x0 0x02950000 0x0 0x10000>,	/* PAGE2 */
		      <0x0 0x02960000 0x0 0x10000>,	/* PAGE3 */
		      <0x0 0x02970000 0x0 0x10000>;	/* PAGE4 */
		interrupts = <0 0 0x04
			      0 1 0x04
			      0 2 0x04
			      0 3 0x04
			      0 4 0x04
			      0 5 0x04
			      0 6 0x04
			      0 7 0x04
			      0 8 0x04
			      0 9 0x04
			      0 10 0x04
			      0 11 0x04
			      0 12 0x04
			      0 13 0x04
			      0 14 0x04
			      0 15 0x04
			      0 16 0x04
			      0 17 0x04
			      0 18 0x04
			      0 19 0x04
			      0 20 0x04
			      0 21 0x04
			      0 22 0x04
			      0 23 0x04
			      0 24 0x04
			      0 25 0x04
			      0 26 0x04
			      0 27 0x04
			      0 28 0x04
			      0 29 0x04
			      0 30 0x04
			      0 31 0x04>;
		#dma-cells = <1>;
		dma-channels = <32>;
		status = "disabled";
	};

	tegra_axbar: ahub {
		compatible = "nvidia,tegra210-axbar";
		reg = <0x0 0x02900800 0x0 0x800>;
		status = "disabled";

		#address-cells = <1>;
		#size-cells = <1>;
		ranges = <0x02900000 0x0 0x02900000 0x00020000>;

		tegra_admaif: admaif@0290F000 {
			compatible = "nvidia,tegra210-admaif";
			reg = <0x0290F000 0x1000>;
			dmas = <&adma 1>, <&adma 1>, <&adma 2>, <&adma 2>,
				<&adma 3>, <&adma 3>, <&adma 4>, <&adma 4>,
				<&adma 5>, <&adma 5>, <&adma 6>, <&adma 6>,
				<&adma 7>, <&adma 7>, <&adma 8>, <&adma 8>,
				<&adma 9>, <&adma 9>, <&adma 10>, <&adma 10>,
				<&adma 11>, <&adma 11>, <&adma 12>, <&adma 12>,
				<&adma 13>, <&adma 13>, <&adma 14>, <&adma 14>,
				<&adma 15>, <&adma 15>, <&adma 16>, <&adma 16>,
				<&adma 17>, <&adma 17>, <&adma 18>, <&adma 18>,
				<&adma 19>, <&adma 19>, <&adma 20>, <&adma 20>;
			dma-names = "rx1", "tx1", "rx2", "tx2", "rx3", "tx3",
				"rx4", "tx4", "rx5", "tx5", "rx6", "tx6",
				"rx7", "tx7", "rx8", "tx8", "rx9", "tx9",
				"rx10", "tx10", "rx11", "tx11", "rx12", "tx12",
				"rx13", "tx13",	"rx14", "tx14", "rx15", "tx15",
				"rx16", "tx16",	"rx17", "tx17", "rx18", "tx18",
				"rx19", "tx19",	"rx20", "tx20";
			status = "disabled";
		};

		tegra_sfc1: sfc@02902000 {
			compatible = "nvidia,tegra210-sfc";
			reg = <0x02902000 0x200>;
			nvidia,ahub-sfc-id = <0>;
			status = "disabled";
		};

		tegra_sfc2: sfc@02902200 {
			compatible = "nvidia,tegra210-sfc";
			reg = <0x02902200 0x200>;
			nvidia,ahub-sfc-id = <1>;
			status = "disabled";
		};

		tegra_sfc3: sfc@02902400 {
			compatible = "nvidia,tegra210-sfc";
			reg = <0x02902400 0x200>;
			nvidia,ahub-sfc-id = <2>;
			status = "disabled";
		};

		tegra_sfc4: sfc@02902600 {
			compatible = "nvidia,tegra210-sfc";
			reg = <0x02902600 0x200>;
			nvidia,ahub-sfc-id = <3>;
			status = "disabled";
		};

		tegra_spkprot: spkprot@702d8c00 {
			compatible = "nvidia,tegra210-spkprot";
			reg = <0x702d8c00 0x400>;
			nvidia,ahub-spkprot-id = <0>;
			status = "disabled";
		};

		tegra_amixer: amixer@0290BB00 {
			compatible = "nvidia,tegra210-amixer";
			reg = <0x0290BB00 0x800>;
			nvidia,ahub-amixer-id = <0>;
			status = "disabled";
		};

		tegra_i2s1: i2s@02901000 {
			compatible = "nvidia,tegra210-i2s";
			reg = <0x02901000 0x100>;
			nvidia,ahub-i2s-id = <0>;
			status = "disabled";
		};

		tegra_i2s2: i2s@02901100 {
			compatible = "nvidia,tegra210-i2s";
			reg = <0x02901100 0x100>;
			nvidia,ahub-i2s-id = <1>;
			status = "disabled";
		};

		tegra_i2s3: i2s@02901200 {
			compatible = "nvidia,tegra210-i2s";
			reg = <0x02901200 0x100>;
			nvidia,ahub-i2s-id = <2>;
			status = "disabled";
		};

		tegra_i2s4: i2s@02901300 {
			compatible = "nvidia,tegra210-i2s";
			reg = <0x02901300 0x100>;
			nvidia,ahub-i2s-id = <3>;
			status = "disabled";
		};

		tegra_i2s5: i2s@02901400 {
			compatible = "nvidia,tegra210-i2s";
			reg = <0x02901400 0x100>;
			nvidia,ahub-i2s-id = <4>;
			status = "disabled";
		};

		tegra_i2s6: i2s@02901500 {
			compatible = "nvidia,tegra210-i2s";
			reg = <0x02901500 0x100>;
			nvidia,ahub-i2s-id = <5>;
			status = "disabled";
		};

		tegra_amx1: amx@02903000 {
			compatible = "nvidia,tegra210-amx";
			reg = <0x02903000 0x100>;
			nvidia,ahub-amx-id = <0>;
			status = "disabled";
		};

		tegra_amx2: amx@02903100 {
			compatible = "nvidia,tegra210-amx";
			reg = <0x02903100 0x100>;
			nvidia,ahub-amx-id = <1>;
			status = "disabled";
		};

		tegra_amx3: amx@02903200 {
			compatible = "nvidia,tegra210-amx";
			reg = <0x02903200 0x100>;
			nvidia,ahub-amx-id = <2>;
			status = "disabled";
		};

		tegra_amx4: amx@02903300 {
			compatible = "nvidia,tegra210-amx";
			reg = <0x02903300 0x100>;
			nvidia,ahub-amx-id = <3>;
			status = "disabled";
		};

		tegra_adx1: adx@02903800 {
			compatible = "nvidia,tegra210-adx";
			reg = <0x02903800 0x100>;
			nvidia,ahub-adx-id = <0>;
			status = "disabled";
		};

		tegra_adx2: adx@02903900 {
			compatible = "nvidia,tegra210-adx";
			reg = <0x02903900 0x100>;
			nvidia,ahub-adx-id = <1>;
			status = "disabled";
		};

		tegra_adx3: adx@02903a00 {
			compatible = "nvidia,tegra210-adx";
			reg = <0x02903a00 0x100>;
			nvidia,ahub-adx-id = <2>;
			status = "disabled";
		};

		tegra_adx4: adx@02903b00 {
			compatible = "nvidia,tegra210-adx";
			reg = <0x02903b00 0x100>;
			nvidia,ahub-adx-id = <3>;
			status = "disabled";
		};

		tegra_dmic1: dmic@02904000 {
			compatible = "nvidia,tegra210-dmic";
			reg = <0x02904000 0x100>;
			nvidia,ahub-dmic-id = <0>;
			status = "disabled";
		};

		tegra_dmic2: dmic@02904100 {
			compatible = "nvidia,tegra210-dmic";
			reg = <0x02904100 0x100>;
			nvidia,ahub-dmic-id = <1>;
			status = "disabled";
		};

		tegra_dmic3: dmic@02904200 {
			compatible = "nvidia,tegra210-dmic";
			reg = <0x02904200 0x100>;
			nvidia,ahub-dmic-id = <2>;
			status = "disabled";
		};

		tegra_dmic4: dmic@02904300 {
			compatible = "nvidia,tegra210-dmic";
			reg = <0x02904300 0x100>;
			nvidia,ahub-dmic-id = <3>;
			status = "disabled";
		};

		tegra_afc1: afc@02907000 {
			compatible = "nvidia,tegra210-afc";
			reg = <0x02907000 0x100>;
			nvidia,ahub-afc-id = <0>;
			status = "disabled";
		};

		tegra_afc2: afc@02907100 {
			compatible = "nvidia,tegra210-afc";
			reg = <0x02907100 0x100>;
			nvidia,ahub-afc-id = <1>;
			status = "disabled";
		};

		tegra_afc3: afc@02907200 {
			compatible = "nvidia,tegra210-afc";
			reg = <0x02907200 0x100>;
			nvidia,ahub-afc-id = <2>;
			status = "disabled";
		};

		tegra_afc4: afc@02907300 {
			compatible = "nvidia,tegra210-afc";
			reg = <0x02907300 0x100>;
			nvidia,ahub-afc-id = <3>;
			status = "disabled";
		};

		tegra_afc5: afc@02907400 {
			compatible = "nvidia,tegra210-afc";
			reg = <0x02907400 0x100>;
			nvidia,ahub-afc-id = <4>;
			status = "disabled";
		};

		tegra_afc6: afc@02907500 {
			compatible = "nvidia,tegra210-afc";
			reg = <0x02907500 0x100>;
			nvidia,ahub-afc-id = <5>;
			status = "disabled";
		};

		tegra_mvc1: mvc@0290A000 {
			compatible = "nvidia,tegra210-mvc";
			reg = <0x0290A000 0x200>;
			nvidia,ahub-mvc-id = <0>;
			status = "disabled";
		};

		tegra_mvc2: mvc@0290A200 {
			compatible = "nvidia,tegra210-mvc";
			reg = <0x0290A200 0x200>;
			nvidia,ahub-mvc-id = <1>;
			status = "disabled";
		};

		tegra_spdif: spdif@02906000 {
			compatible = "nvidia,tegra210-spdif";
			reg = <0x02906000 0x200>;
			nvidia,ahub-spdif-id = <0>;
			status = "disabled";
		};

		tegra_iqc1: iqc@2290E000 {
			compatible = "nvidia,tegra210-iqc";
			reg = <0x2290E000 0x200>;
			nvidia,ahub-iqc-id = <0>;
			status = "disabled";
		};

		tegra_asrc: asrc@02910000 {
			compatible = "nvidia,tegra186-asrc";
			reg = <0x02910000 0x2000>;
			nvidia,ahub-asrc-id = <0>;
			status = "disabled";
		};

		tegra_arad: arad@0290E400 {
			compatible = "nvidia,tegra186-arad";
			reg = <0x0290E400 0x400>;
			interrupts = <0 56 0x4>;
			nvidia,ahub-arad-id = <0>;
			status = "disabled";
		};

		tegra_ope1: ope@02908000 {
			compatible = "nvidia,tegra210-ope";
			reg = <0x02908000 0x100>,
			      <0x02908100 0x100>,
			      <0x02908200 0x200>;
			nvidia,ahub-ope-id = <0>;
			status = "disabled";
		};

		tegra_dspk1: dspk@02905000 {
			compatible = "nvidia,tegra186-dspk";
			reg = <0x02905000 0x100>;
			nvidia,ahub-dspk-id = <0>;
			status = "disabled";
		};

		tegra_dspk2: dspk@02905100 {
			compatible = "nvidia,tegra186-dspk";
			reg = <0x02905100 0x100>;
			nvidia,ahub-dspk-id = <1>;
			status = "disabled";
		};
	};

	spdif_dit0: spdif-dit.0@0 {
		compatible = "linux,spdif-dit";
		reg = <0x0 0x0 0x0 0x0>;
	};

	spdif_dit1: spdif-dit.1@1 {
		compatible = "linux,spdif-dit";
		reg = <0x0 0x1 0x0 0x0>;
	};

	spdif_dit2: spdif-dit.2@2 {
		compatible = "linux,spdif-dit";
		reg = <0x0 0x2 0x0 0x0>;
	};

	spdif_dit3: spdif-dit.3@3 {
		compatible = "linux,spdif-dit";
		reg = <0x0 0x03 0x0 0x0>;
	};

	agic-controller@2a41000 {
		compatible = "nvidia,tegra18x-agic";
		interrupt-controller;
		no-gic-extension;
		not-per-cpu;
		reg = <0x0 0x02a41000 0x0 0x1000>,
		      <0x0 0x02a42000 0x0 0x2000>;
		interrupts = <0 145 0xf04>;
		status = "disabled";
	};

	tegra_adsp_audio: adsp_audio {
		compatible = "nvidia,tegra210-adsp-audio";
		power-domains = <&ape_pd>;
		status = "disabled";
        };

	adsp@2993000 {
	     compatible = "nvidia,tegra18x-adsp";
	     power-domains = <&ape_pd>;
	     reg = <0x0 0x02993000 0x0 0x1000>, /* AMC */
		   <0x0 0x02990000 0x0 0x2000>, /* AMISC */
		   <0x0 0x0 0x0 0x1>, /* ABRIDGE */
		   <0x0 0x0290C800 0x0 0x1>, /* FPGA RESET REG */
		   <0x0 0x40000000 0x0 0xC0000000>, /* DRAM MAP1 */
		   <0x0 0x0 0x0 0x1>; /* DRAM MAP2 */
	     nvidia,adsp_unit_fpga;
	     nvidia,adsp_unit_fpga_reset = <0x07F00040 0x00000040>;
	     nvidia,adsp_mem = <0x8f000000 0x01000000>, /* ADSP OS */
			       <0x8f800000 0x00800000>, /* ADSP APP */
			       <0x3F800000 0x00018000>; /* ARAM ALIAS 0 */
	     status = "disabled";
	};

	watchdog@30c0000 {
		compatible = "nvidia,tegra-wdt-t18x";
		reg = <0x0 0x030c0000 0x0 0x10000>, /* WDT0 */
		      <0x0 0x03090000 0x0 0x10000>; /* TMR7 */
		interrupts = <1 15 0xf01>;
		nvidia,wdt-cpu-id = <4>; /* denver cpu */
		nvidia,expiry-count = <5>;
		nvidia,enable-on-init;
		nvidia,heartbeat-init = <120>;
		nvidia,disable-debug-reset;
		nvidia,disable-por-reset;
		status = "disabled";
	};

	watchdog@30d0000 {
		compatible = "nvidia,tegra-wdt-t18x";
		reg = <0x0 0x030d0000 0x0 0x10000>, /* WDT1 */
		      <0x0 0x030a0000 0x0 0x10000>; /* TMR8 */
		interrupts = <1 15 0xf01>;
		nvidia,wdt-cpu-id = <0>; /* ARM cpu */
		nvidia,expiry-count = <5>;
		nvidia,enable-on-init;
		nvidia,heartbeat-init = <120>;
		nvidia,disable-debug-reset;
		nvidia,disable-por-reset;
		status = "disabled";
	};

	tegra_fiq_debugger {
		compatible = "nvidia,fiq-debugger";
		use-console-port;
		interrupts = <0 17 0x4>;
	};

	roc-flush@e080000 {
		compatible = "nvidia,tegra186-roc-flush";
		reg = <0x0 0x0e080000 0x0 0x10000>;
		status = "disabled";
	};

	clocks {
	     compatible = "simple-bus";
             #address-cells = <1>;
	     #size-cells = <0>;

	     clk32k_in: clk32k_in@0 {
		compatible = "fixed-clock";
		reg = <0>;
		#clock-cells = <0>;
		clock-frequency = <32768>;
		status = "disabled";
	     };
	};

	mttcan0: mttcan@c310000 {
		compatible = "bosch,mttcan";
		reg = <0x00 0x0c310000 0x00 0x400>,
		      <0x00 0x0c311000 0x00 0x32>,
		      <0x00 0x0c312000 0x00 0x1000>,
		      <0x00 0x05b10004 0x00 0x08>;
		reg-names = "can-regs", "glue-regs", "msg-ram", "car-reg";
		interrupts = <0 40 0x04 >;
		status = "disabled";
	};

	mttcan1: mttcan@c320000 {
		compatible = "bosch,mttcan";
		reg = <0x00 0x0c320000 0x00 0x400>,
		      <0x00 0x0c321000 0x00 0x32>,
		      <0x00 0x0c322000 0x00 0x1000>,
		      <0x00 0x05b20004 0x00 0x08>;
		reg-names = "can-regs", "glue-regs", "msg-ram", "car-reg";
		interrupts = <0 42 0x04 >;
		status = "disabled";
	};

	cpuidle {
		compatible = "nvidia,tegra18x-cpuidle";
		status = "disabled";
	};

	sce_ast0: ast@b040000 {
		compatible = "nvidia,tegra186-ast";
		reg = <0 0x0b040000 0 0x10000>;
		status = "disabled";
	};

	sce_ast1: ast@b050000 {
		compatible = "nvidia,tegra186-ast";
		reg = <0 0x0b050000 0 0x10000>;
		status = "disabled";
	};

	aon_ast0: ast@c040000 {
		compatible = "nvidia,tegra186-ast";
		reg = <0 0x0c040000 0 0x10000>;
		status = "disabled";
	};

	aon_ast1: ast@c050000 {
		compatible = "nvidia,tegra186-ast";
		reg = <0 0x0c050000 0 0x10000>;
		status = "disabled";
	};

	cpufreq@e070000 {
		compatible = "nvidia,tegra18x-cpufreq";
		reg = <0x0 0x0e070000 0x0 0x1000>, /* M/Denver cluster */
		      <0x0 0x0e060000 0x0 0x1000>; /* B/ARM cluster */
		clocks = <&tegra_car TEGRA186_CLK_EMC>,
			 <&tegra_car TEGRA186_CLK_EMC>;
		clock-names = "emc0", "emc1";
		status = "disabled";
	};

	rtc@c2a0000 {
		compatible = "nvidia,tegra-rtc";
		reg = <0x0 0x0c2a0000 0x0 0x100>;
		interrupts = <0 18 0x04>;
		status = "disabled";
	};
};
